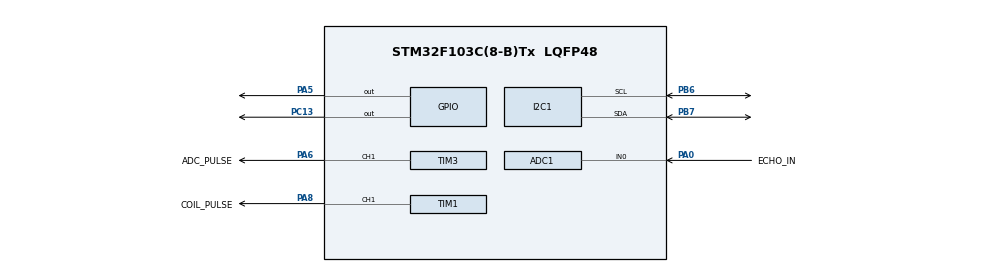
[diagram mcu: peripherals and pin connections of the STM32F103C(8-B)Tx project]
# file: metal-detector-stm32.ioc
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ADC1.Channel-0\#ChannelRegularConversion=ADC_CHANNEL_0
ADC1.ExternalTrigConv=ADC_EXTERNALTRIGCONV_T3_TRGO
ADC1.NbrOfConversionFlag=1
ADC1.Rank-0\#ChannelRegularConversion=1
ADC1.SamplingTime-0\#ChannelRegularConversion=ADC_SAMPLETIME_1CYCLE_5
ADC1.master=1
Dma.ADC1.0.Direction=DMA_PERIPH_TO_MEMORY
Dma.ADC1.0.Instance=DMA1_Channel1
Dma.ADC1.0.MemDataAlignment=DMA_MDATAALIGN_HALFWORD
Dma.ADC1.0.MemInc=DMA_MINC_ENABLE
Dma.ADC1.0.Mode=DMA_NORMAL
Dma.ADC1.0.PeriphDataAlignment=DMA_PDATAALIGN_HALFWORD
Dma.ADC1.0.PeriphInc=DMA_PINC_DISABLE
Dma.ADC1.0.Priority=DMA_PRIORITY_LOW
Dma.Request0=ADC1
Mcu.Family=STM32F1
Mcu.Name=STM32F103C(8-B)Tx
Mcu.Package=LQFP48
NVIC.DMA1_Channel1_IRQn=true\:0\:0\:false\:false\:true\:false\:true
NVIC.PriorityGroup=NVIC_PRIORITYGROUP_4
PA0-WKUP.GPIO_Label=ECHO_IN
PA0-WKUP.Signal=ADCx_IN0
PA13.Mode=Serial_Wire
PA13.Signal=SYS_JTMS-SWDIO
PA14.Mode=Serial_Wire
PA14.Signal=SYS_JTCK-SWCLK
PA5.GPIO_Speed=GPIO_SPEED_FREQ_HIGH
PA5.Signal=GPIO_Output
PA6.GPIO_Label=ADC_PULSE
PA6.Signal=S_TIM3_CH1
PA8.GPIO_Label=COIL_PULSE
PA8.Signal=S_TIM1_CH1
PB6.Mode=I2C
PB6.Signal=I2C1_SCL
PB7.Mode=I2C
PB7.Signal=I2C1_SDA
PC13-TAMPER-RTC.PinState=GPIO_PIN_RESET
PC13-TAMPER-RTC.Signal=GPIO_Output
ProjectManager.HeapSize=0x0
ProjectManager.StackSize=0x4000
ProjectManager.TargetToolchain=Makefile
RCC.ADCPresc=RCC_ADCPCLK2_DIV6
RCC.AHBFreq_Value=64000000
RCC.APB1CLKDivider=RCC_HCLK_DIV2
RCC.APB1Freq_Value=32000000
RCC.APB1TimFreq_Value=64000000
RCC.APB2Freq_Value=64000000
RCC.APB2TimFreq_Value=64000000
RCC.HCLKFreq_Value=64000000
RCC.PLLMUL=RCC_PLL_MUL16
RCC.SYSCLKFreq_VALUE=64000000
RCC.SYSCLKSource=RCC_SYSCLKSOURCE_PLLCLK
RCC.USBFreq_Value=64000000
SH.ADCx_IN0.0=ADC1_IN0,IN0
SH.S_TIM1_CH1.0=TIM1_CH1,PWM Generation1 CH1
SH.S_TIM3_CH1.0=TIM3_CH1,PWM Generation1 CH1
TIM1.Channel-PWM\ Generation1\ CH1=TIM_CHANNEL_1
TIM1.Channel-PWM\ Generation2\ No\ Output=TIM_CHANNEL_2
TIM1.OCMode_PWM-PWM\ Generation2\ No\ Output=TIM_OCMODE_PWM2
TIM1.OCPolarity_2=TIM_OCPOLARITY_HIGH
TIM1.Period=20000
TIM1.Prescaler=63
TIM1.Pulse-PWM\ Generation1\ CH1=200
TIM1.Pulse-PWM\ Generation2\ No\ Output=300
TIM1.TIM_MasterOutputTrigger=TIM_TRGO_OC2REF
TIM1.TIM_MasterSlaveMode=TIM_MASTERSLAVEMODE_ENABLE
TIM3.Channel-PWM\ Generation1\ CH1=TIM_CHANNEL_1
TIM3.Period=100
TIM3.Pulse-PWM\ Generation1\ CH1=50
TIM3.TIM_MasterOutputTrigger=TIM_TRGO_OC1REF
TIM3.TIM_MasterSlaveMode=TIM_MASTERSLAVEMODE_ENABLE
VP_TIM1_VS_ClockSourceINT.Mode=Internal
VP_TIM1_VS_no_output2.Mode=PWM Generation2 No Output
VP_TIM3_VS_ClockSourceINT.Mode=Internal
VP_TIM3_VS_ClockSourceITR.Mode=TriggerSource_ITR0
VP_TIM3_VS_ControllerModeTrigger.Mode=Trigger Mode
board=custom

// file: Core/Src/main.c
/* USER CODE BEGIN Header */
/**
  ******************************************************************************
  * @file           : main.c
  * @brief          : Main program body
  ******************************************************************************
  * @attention
  *
  * <h2><center>&copy; Copyright (c) 2021 STMicroelectronics.
  * All rights reserved.</center></h2>
  *
  * This software component is licensed by ST under BSD 3-Clause license,
  * the "License"; You may not use this file except in compliance with the
  * License. You may obtain a copy of the License at:
  *                        opensource.org/licenses/BSD-3-Clause
  *
  ******************************************************************************
  */
/* USER CODE END Header */
#include "main.h"

void SystemClock_Config(void);
static void MX_GPIO_Init(void);
static void MX_DMA_Init(void);
static void MX_ADC1_Init(void);
static void MX_I2C1_Init(void);
static void MX_TIM1_Init(void);
static void MX_TIM3_Init(void);

int main(void)
{

  /* MCU Configuration--------------------------------------------------------*/

  /* Reset of all peripherals, Initializes the Flash interface and the Systick. */

  LL_APB2_GRP1_EnableClock(LL_APB2_GRP1_PERIPH_AFIO);
  LL_APB1_GRP1_EnableClock(LL_APB1_GRP1_PERIPH_PWR);

  NVIC_SetPriorityGrouping(NVIC_PRIORITYGROUP_4);

  /* System interrupt init*/

  /** NOJTAG: JTAG-DP Disabled and SW-DP Enabled
  */
  LL_GPIO_AF_Remap_SWJ_NOJTAG();

  /* Configure the system clock */
  SystemClock_Config();

  /* Initialize all configured peripherals */
  MX_GPIO_Init();
  MX_DMA_Init();
  MX_ADC1_Init();
  MX_I2C1_Init();
  MX_TIM1_Init();
  MX_TIM3_Init();
  /* USER CODE BEGIN 2 */
  main_task();
  /* USER CODE END 2 */

  /* Infinite loop */
  while (1)
  {

  }
}

void SystemClock_Config(void)
{
  LL_FLASH_SetLatency(LL_FLASH_LATENCY_2);
  while(LL_FLASH_GetLatency()!= LL_FLASH_LATENCY_2)
  {
  }
  LL_RCC_HSI_SetCalibTrimming(16);
  LL_RCC_HSI_Enable();

   /* Wait till HSI is ready */
  while(LL_RCC_HSI_IsReady() != 1)
  {

  }
  LL_RCC_PLL_ConfigDomain_SYS(LL_RCC_PLLSOURCE_HSI_DIV_2, LL_RCC_PLL_MUL_16);
  LL_RCC_PLL_Enable();

   /* Wait till PLL is ready */
  while(LL_RCC_PLL_IsReady() != 1)
  {

  }
  LL_RCC_SetAHBPrescaler(LL_RCC_SYSCLK_DIV_1);
  LL_RCC_SetAPB1Prescaler(LL_RCC_APB1_DIV_2);
  LL_RCC_SetAPB2Prescaler(LL_RCC_APB2_DIV_1);
  LL_RCC_SetSysClkSource(LL_RCC_SYS_CLKSOURCE_PLL);

   /* Wait till System clock is ready */
  while(LL_RCC_GetSysClkSource() != LL_RCC_SYS_CLKSOURCE_STATUS_PLL)
  {

  }
  LL_Init1msTick(64000000);
  LL_SetSystemCoreClock(64000000);
  LL_RCC_SetADCClockSource(LL_RCC_ADC_CLKSRC_PCLK2_DIV_6);
}

static void MX_ADC1_Init(void)
{

  LL_ADC_InitTypeDef ADC_InitStruct = {0};
  LL_ADC_CommonInitTypeDef ADC_CommonInitStruct = {0};
  LL_ADC_REG_InitTypeDef ADC_REG_InitStruct = {0};

  LL_GPIO_InitTypeDef GPIO_InitStruct = {0};

  /* Peripheral clock enable */
  LL_APB2_GRP1_EnableClock(LL_APB2_GRP1_PERIPH_ADC1);

  LL_APB2_GRP1_EnableClock(LL_APB2_GRP1_PERIPH_GPIOA);
  /**ADC1 GPIO Configuration
  PA0-WKUP   ------> ADC1_IN0
  */
  GPIO_InitStruct.Pin = ECHO_IN_Pin;
  GPIO_InitStruct.Mode = LL_GPIO_MODE_ANALOG;
  LL_GPIO_Init(ECHO_IN_GPIO_Port, &GPIO_InitStruct);

  /* ADC1 DMA Init */

  /* ADC1 Init */
  LL_DMA_SetDataTransferDirection(DMA1, LL_DMA_CHANNEL_1, LL_DMA_DIRECTION_PERIPH_TO_MEMORY);

  LL_DMA_SetChannelPriorityLevel(DMA1, LL_DMA_CHANNEL_1, LL_DMA_PRIORITY_LOW);

  LL_DMA_SetMode(DMA1, LL_DMA_CHANNEL_1, LL_DMA_MODE_NORMAL);

  LL_DMA_SetPeriphIncMode(DMA1, LL_DMA_CHANNEL_1, LL_DMA_PERIPH_NOINCREMENT);

  LL_DMA_SetMemoryIncMode(DMA1, LL_DMA_CHANNEL_1, LL_DMA_MEMORY_INCREMENT);

  LL_DMA_SetPeriphSize(DMA1, LL_DMA_CHANNEL_1, LL_DMA_PDATAALIGN_HALFWORD);

  LL_DMA_SetMemorySize(DMA1, LL_DMA_CHANNEL_1, LL_DMA_MDATAALIGN_HALFWORD);

  /** Common config
  */
  ADC_InitStruct.DataAlignment = LL_ADC_DATA_ALIGN_RIGHT;
  ADC_InitStruct.SequencersScanMode = LL_ADC_SEQ_SCAN_DISABLE;
  LL_ADC_Init(ADC1, &ADC_InitStruct);
  ADC_CommonInitStruct.Multimode = LL_ADC_MULTI_INDEPENDENT;
  LL_ADC_CommonInit(__LL_ADC_COMMON_INSTANCE(ADC1), &ADC_CommonInitStruct);
  ADC_REG_InitStruct.TriggerSource = LL_ADC_REG_TRIG_EXT_TIM3_TRGO;
  ADC_REG_InitStruct.SequencerLength = LL_ADC_REG_SEQ_SCAN_DISABLE;
  ADC_REG_InitStruct.SequencerDiscont = LL_ADC_REG_SEQ_DISCONT_DISABLE;
  ADC_REG_InitStruct.ContinuousMode = LL_ADC_REG_CONV_SINGLE;
  ADC_REG_InitStruct.DMATransfer = LL_ADC_REG_DMA_TRANSFER_UNLIMITED;
  LL_ADC_REG_Init(ADC1, &ADC_REG_InitStruct);
  /** Configure Regular Channel
  */
  LL_ADC_REG_SetSequencerRanks(ADC1, LL_ADC_REG_RANK_1, LL_ADC_CHANNEL_0);
  LL_ADC_SetChannelSamplingTime(ADC1, LL_ADC_CHANNEL_0, LL_ADC_SAMPLINGTIME_1CYCLE_5);

}

static void MX_I2C1_Init(void)
{

  LL_I2C_InitTypeDef I2C_InitStruct = {0};

  LL_GPIO_InitTypeDef GPIO_InitStruct = {0};

  LL_APB2_GRP1_EnableClock(LL_APB2_GRP1_PERIPH_GPIOB);
  /**I2C1 GPIO Configuration
  PB6   ------> I2C1_SCL
  PB7   ------> I2C1_SDA
  */
  GPIO_InitStruct.Pin = LL_GPIO_PIN_6|LL_GPIO_PIN_7;
  GPIO_InitStruct.Mode = LL_GPIO_MODE_ALTERNATE;
  GPIO_InitStruct.Speed = LL_GPIO_SPEED_FREQ_HIGH;
  GPIO_InitStruct.OutputType = LL_GPIO_OUTPUT_OPENDRAIN;
  LL_GPIO_Init(GPIOB, &GPIO_InitStruct);

  /* Peripheral clock enable */
  LL_APB1_GRP1_EnableClock(LL_APB1_GRP1_PERIPH_I2C1);

  /** I2C Initialization
  */
  LL_I2C_DisableOwnAddress2(I2C1);
  LL_I2C_DisableGeneralCall(I2C1);
  LL_I2C_EnableClockStretching(I2C1);
  I2C_InitStruct.PeripheralMode = LL_I2C_MODE_I2C;
  I2C_InitStruct.ClockSpeed = 100000;
  I2C_InitStruct.DutyCycle = LL_I2C_DUTYCYCLE_2;
  I2C_InitStruct.OwnAddress1 = 0;
  I2C_InitStruct.TypeAcknowledge = LL_I2C_ACK;
  I2C_InitStruct.OwnAddrSize = LL_I2C_OWNADDRESS1_7BIT;
  LL_I2C_Init(I2C1, &I2C_InitStruct);
  LL_I2C_SetOwnAddress2(I2C1, 0);

}

static void MX_TIM1_Init(void)
{

  LL_TIM_InitTypeDef TIM_InitStruct = {0};
  LL_TIM_OC_InitTypeDef TIM_OC_InitStruct = {0};
  LL_TIM_BDTR_InitTypeDef TIM_BDTRInitStruct = {0};

  LL_GPIO_InitTypeDef GPIO_InitStruct = {0};

  /* Peripheral clock enable */
  LL_APB2_GRP1_EnableClock(LL_APB2_GRP1_PERIPH_TIM1);

  TIM_InitStruct.Prescaler = 63;
  TIM_InitStruct.CounterMode = LL_TIM_COUNTERMODE_UP;
  TIM_InitStruct.Autoreload = 20000;
  TIM_InitStruct.ClockDivision = LL_TIM_CLOCKDIVISION_DIV1;
  TIM_InitStruct.RepetitionCounter = 0;
  LL_TIM_Init(TIM1, &TIM_InitStruct);
  LL_TIM_DisableARRPreload(TIM1);
  LL_TIM_SetClockSource(TIM1, LL_TIM_CLOCKSOURCE_INTERNAL);
  LL_TIM_OC_EnablePreload(TIM1, LL_TIM_CHANNEL_CH1);
  TIM_OC_InitStruct.OCMode = LL_TIM_OCMODE_PWM1;
  TIM_OC_InitStruct.OCState = LL_TIM_OCSTATE_DISABLE;
  TIM_OC_InitStruct.OCNState = LL_TIM_OCSTATE_DISABLE;
  TIM_OC_InitStruct.CompareValue = 200;
  TIM_OC_InitStruct.OCPolarity = LL_TIM_OCPOLARITY_HIGH;
  TIM_OC_InitStruct.OCNPolarity = LL_TIM_OCPOLARITY_HIGH;
  TIM_OC_InitStruct.OCIdleState = LL_TIM_OCIDLESTATE_LOW;
  TIM_OC_InitStruct.OCNIdleState = LL_TIM_OCIDLESTATE_LOW;
  LL_TIM_OC_Init(TIM1, LL_TIM_CHANNEL_CH1, &TIM_OC_InitStruct);
  LL_TIM_OC_DisableFast(TIM1, LL_TIM_CHANNEL_CH1);
  LL_TIM_OC_EnablePreload(TIM1, LL_TIM_CHANNEL_CH2);
  TIM_OC_InitStruct.OCMode = LL_TIM_OCMODE_PWM2;
  TIM_OC_InitStruct.CompareValue = 300;
  LL_TIM_OC_Init(TIM1, LL_TIM_CHANNEL_CH2, &TIM_OC_InitStruct);
  LL_TIM_OC_DisableFast(TIM1, LL_TIM_CHANNEL_CH2);
  LL_TIM_SetTriggerOutput(TIM1, LL_TIM_TRGO_OC2REF);
  LL_TIM_EnableMasterSlaveMode(TIM1);
  TIM_BDTRInitStruct.OSSRState = LL_TIM_OSSR_DISABLE;
  TIM_BDTRInitStruct.OSSIState = LL_TIM_OSSI_DISABLE;
  TIM_BDTRInitStruct.LockLevel = LL_TIM_LOCKLEVEL_OFF;
  TIM_BDTRInitStruct.DeadTime = 0;
  TIM_BDTRInitStruct.BreakState = LL_TIM_BREAK_DISABLE;
  TIM_BDTRInitStruct.BreakPolarity = LL_TIM_BREAK_POLARITY_HIGH;
  TIM_BDTRInitStruct.AutomaticOutput = LL_TIM_AUTOMATICOUTPUT_DISABLE;
  LL_TIM_BDTR_Init(TIM1, &TIM_BDTRInitStruct);
  LL_APB2_GRP1_EnableClock(LL_APB2_GRP1_PERIPH_GPIOA);
  /**TIM1 GPIO Configuration
  PA8   ------> TIM1_CH1
  */
  GPIO_InitStruct.Pin = COIL_PULSE_Pin;
  GPIO_InitStruct.Mode = LL_GPIO_MODE_ALTERNATE;
  GPIO_InitStruct.Speed = LL_GPIO_SPEED_FREQ_LOW;
  GPIO_InitStruct.OutputType = LL_GPIO_OUTPUT_PUSHPULL;
  LL_GPIO_Init(COIL_PULSE_GPIO_Port, &GPIO_InitStruct);

}

static void MX_TIM3_Init(void)
{

  LL_TIM_InitTypeDef TIM_InitStruct = {0};
  LL_TIM_OC_InitTypeDef TIM_OC_InitStruct = {0};

  LL_GPIO_InitTypeDef GPIO_InitStruct = {0};

  /* Peripheral clock enable */
  LL_APB1_GRP1_EnableClock(LL_APB1_GRP1_PERIPH_TIM3);

  TIM_InitStruct.Prescaler = 0;
  TIM_InitStruct.CounterMode = LL_TIM_COUNTERMODE_UP;
  TIM_InitStruct.Autoreload = 100;
  TIM_InitStruct.ClockDivision = LL_TIM_CLOCKDIVISION_DIV1;
  LL_TIM_Init(TIM3, &TIM_InitStruct);
  LL_TIM_DisableARRPreload(TIM3);
  LL_TIM_SetClockSource(TIM3, LL_TIM_CLOCKSOURCE_INTERNAL);
  LL_TIM_OC_EnablePreload(TIM3, LL_TIM_CHANNEL_CH1);
  TIM_OC_InitStruct.OCMode = LL_TIM_OCMODE_PWM1;
  TIM_OC_InitStruct.OCState = LL_TIM_OCSTATE_DISABLE;
  TIM_OC_InitStruct.OCNState = LL_TIM_OCSTATE_DISABLE;
  TIM_OC_InitStruct.CompareValue = 50;
  TIM_OC_InitStruct.OCPolarity = LL_TIM_OCPOLARITY_HIGH;
  LL_TIM_OC_Init(TIM3, LL_TIM_CHANNEL_CH1, &TIM_OC_InitStruct);
  LL_TIM_OC_DisableFast(TIM3, LL_TIM_CHANNEL_CH1);
  LL_TIM_SetTriggerInput(TIM3, LL_TIM_TS_ITR0);
  LL_TIM_SetSlaveMode(TIM3, LL_TIM_SLAVEMODE_TRIGGER);
  LL_TIM_DisableIT_TRIG(TIM3);
  LL_TIM_DisableDMAReq_TRIG(TIM3);
  LL_TIM_SetTriggerOutput(TIM3, LL_TIM_TRGO_OC1REF);
  LL_TIM_EnableMasterSlaveMode(TIM3);
  LL_APB2_GRP1_EnableClock(LL_APB2_GRP1_PERIPH_GPIOA);
  /**TIM3 GPIO Configuration
  PA6   ------> TIM3_CH1
  */
  GPIO_InitStruct.Pin = ADC_PULSE_Pin;
  GPIO_InitStruct.Mode = LL_GPIO_MODE_ALTERNATE;
  GPIO_InitStruct.Speed = LL_GPIO_SPEED_FREQ_LOW;
  GPIO_InitStruct.OutputType = LL_GPIO_OUTPUT_PUSHPULL;
  LL_GPIO_Init(ADC_PULSE_GPIO_Port, &GPIO_InitStruct);

}

static void MX_DMA_Init(void)
{

  /* Init with LL driver */
  /* DMA controller clock enable */
  LL_AHB1_GRP1_EnableClock(LL_AHB1_GRP1_PERIPH_DMA1);

  /* DMA interrupt init */
  /* DMA1_Channel1_IRQn interrupt configuration */
  NVIC_SetPriority(DMA1_Channel1_IRQn, NVIC_EncodePriority(NVIC_GetPriorityGrouping(),0, 0));
  NVIC_EnableIRQ(DMA1_Channel1_IRQn);

}

static void MX_GPIO_Init(void)
{
  LL_GPIO_InitTypeDef GPIO_InitStruct = {0};

  /* GPIO Ports Clock Enable */
  LL_APB2_GRP1_EnableClock(LL_APB2_GRP1_PERIPH_GPIOC);
  LL_APB2_GRP1_EnableClock(LL_APB2_GRP1_PERIPH_GPIOD);
  LL_APB2_GRP1_EnableClock(LL_APB2_GRP1_PERIPH_GPIOA);
  LL_APB2_GRP1_EnableClock(LL_APB2_GRP1_PERIPH_GPIOB);

  /**/
  LL_GPIO_ResetOutputPin(GPIOC, LL_GPIO_PIN_13);

  /**/
  LL_GPIO_ResetOutputPin(GPIOA, LL_GPIO_PIN_5);

  /**/
  GPIO_InitStruct.Pin = LL_GPIO_PIN_13;
  GPIO_InitStruct.Mode = LL_GPIO_MODE_OUTPUT;
  GPIO_InitStruct.Speed = LL_GPIO_SPEED_FREQ_LOW;
  GPIO_InitStruct.OutputType = LL_GPIO_OUTPUT_PUSHPULL;
  LL_GPIO_Init(GPIOC, &GPIO_InitStruct);

  /**/
  GPIO_InitStruct.Pin = LL_GPIO_PIN_14|LL_GPIO_PIN_15;
  GPIO_InitStruct.Mode = LL_GPIO_MODE_ANALOG;
  LL_GPIO_Init(GPIOC, &GPIO_InitStruct);

  /**/
  GPIO_InitStruct.Pin = LL_GPIO_PIN_0|LL_GPIO_PIN_1;
  GPIO_InitStruct.Mode = LL_GPIO_MODE_ANALOG;
  LL_GPIO_Init(GPIOD, &GPIO_InitStruct);

  /**/
  GPIO_InitStruct.Pin = LL_GPIO_PIN_1|LL_GPIO_PIN_2|LL_GPIO_PIN_3|LL_GPIO_PIN_4
                          |LL_GPIO_PIN_7|LL_GPIO_PIN_9|LL_GPIO_PIN_10|LL_GPIO_PIN_11
                          |LL_GPIO_PIN_12|LL_GPIO_PIN_15;
  GPIO_InitStruct.Mode = LL_GPIO_MODE_ANALOG;
  LL_GPIO_Init(GPIOA, &GPIO_InitStruct);

  /**/
  GPIO_InitStruct.Pin = LL_GPIO_PIN_5;
  GPIO_InitStruct.Mode = LL_GPIO_MODE_OUTPUT;
  GPIO_InitStruct.Speed = LL_GPIO_SPEED_FREQ_HIGH;
  GPIO_InitStruct.OutputType = LL_GPIO_OUTPUT_PUSHPULL;
  LL_GPIO_Init(GPIOA, &GPIO_InitStruct);

  /**/
  GPIO_InitStruct.Pin = LL_GPIO_PIN_0|LL_GPIO_PIN_1|LL_GPIO_PIN_2|LL_GPIO_PIN_10
                          |LL_GPIO_PIN_11|LL_GPIO_PIN_12|LL_GPIO_PIN_13|LL_GPIO_PIN_14
                          |LL_GPIO_PIN_15|LL_GPIO_PIN_3|LL_GPIO_PIN_4|LL_GPIO_PIN_5
                          |LL_GPIO_PIN_8|LL_GPIO_PIN_9;
  GPIO_InitStruct.Mode = LL_GPIO_MODE_ANALOG;
  LL_GPIO_Init(GPIOB, &GPIO_InitStruct);

  /**/
  LL_GPIO_AF_EnableRemap_PD01();

}

void Error_Handler(void)
{
  __disable_irq();
  while (1)
  {
  }
}

/************************ (C) COPYRIGHT STMicroelectronics *****END OF FILE****/
